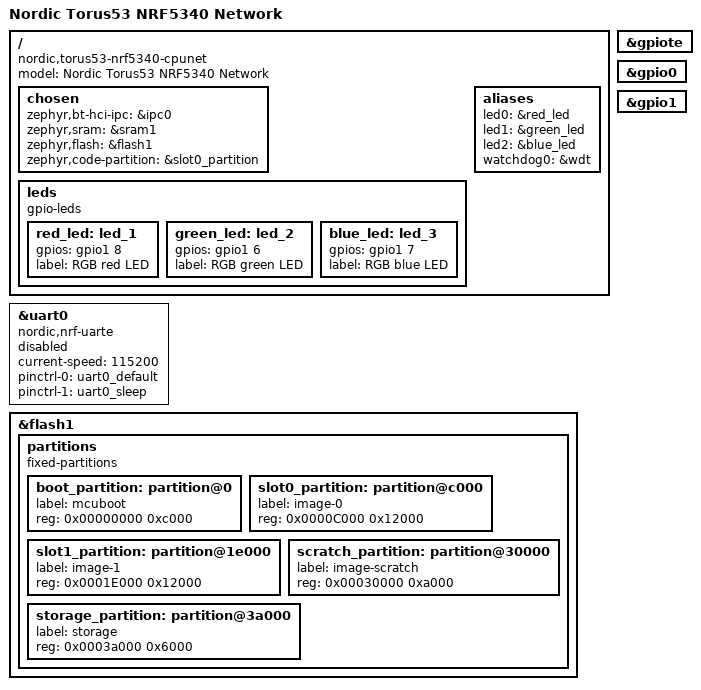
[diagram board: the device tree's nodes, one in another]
/*
 * Copyright (c) 2021 Nordic Semiconductor ASA
 *
 * SPDX-License-Identifier: Apache-2.0
 */

/dts-v1/;
#include <nordic/nrf5340_cpunet_qkaa.dtsi>
#include "torus53_nrf5340_cpunet-pinctrl.dtsi"
#include <zephyr/dt-bindings/input/input-event-codes.h>

/ {
	model = "Nordic Torus53 NRF5340 Network";
	compatible = "nordic,torus53-nrf5340-cpunet";

	chosen {
		zephyr,bt-hci-ipc = &ipc0;
		zephyr,sram = &sram1;
		zephyr,flash = &flash1;
		zephyr,code-partition = &slot0_partition;
	};

	leds {
		compatible = "gpio-leds";
		red_led: led_1 {
			gpios = <&gpio1 8 (GPIO_PULL_DOWN | GPIO_ACTIVE_HIGH)>;
			label = "RGB red LED";
		};
		green_led: led_2 {
			gpios = <&gpio1 6 (GPIO_PULL_DOWN | GPIO_ACTIVE_HIGH)>;
			label = "RGB green LED";
		};
		blue_led: led_3 {
			gpios = <&gpio1 7 (GPIO_PULL_DOWN | GPIO_ACTIVE_HIGH)>;
			label = "RGB blue LED";
		};
	};

	aliases {
		led0 = &red_led;
		led1 = &green_led;
		led2 = &blue_led;
		watchdog0 = &wdt;
	};
};

&gpiote {
	status = "okay";
};

&gpio0 {
	status = "okay";
};

&gpio1 {
	status = "okay";
};

&uart0 {
	compatible = "nordic,nrf-uarte";
	status = "disabled";
	current-speed = <115200>;
	pinctrl-0 = <&uart0_default>;
	pinctrl-1 = <&uart0_sleep>;
	pinctrl-names = "default", "sleep";
};

&flash1 {
	partitions {
		compatible = "fixed-partitions";
		#address-cells = <1>;
		#size-cells = <1>;

		boot_partition: partition@0 {
			label = "mcuboot";
			reg = <0x00000000 0xc000>;
		};
		slot0_partition: partition@c000 {
			label = "image-0";
			reg = <0x0000C000 0x12000>;
		};
		slot1_partition: partition@1e000 {
			label = "image-1";
			reg = <0x0001E000 0x12000>;
		};
		scratch_partition: partition@30000 {
			label = "image-scratch";
			reg = <0x00030000 0xa000>;
		};
		storage_partition: partition@3a000 {
			label = "storage";
			reg = <0x0003a000 0x6000>;
		};
	};
};

/* Include default shared RAM configuration file */
#include <common/nordic/nrf5340_shared_sram_partition.dtsi>
